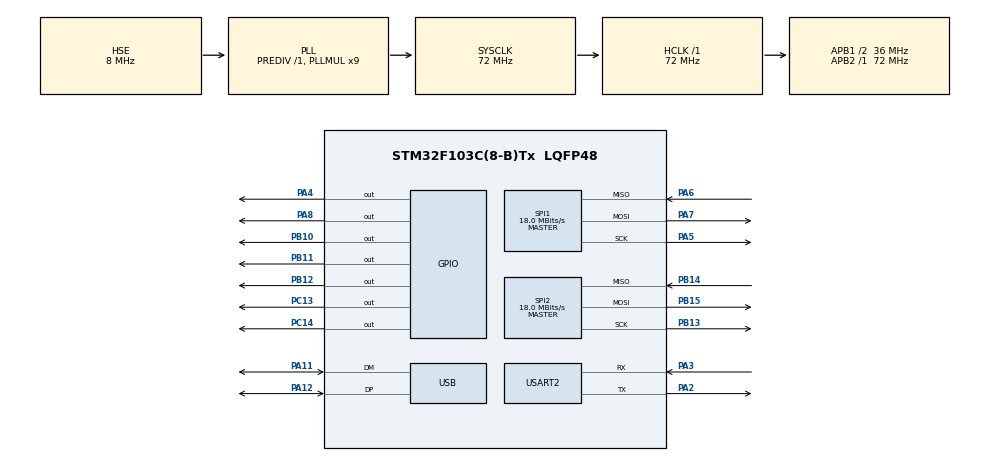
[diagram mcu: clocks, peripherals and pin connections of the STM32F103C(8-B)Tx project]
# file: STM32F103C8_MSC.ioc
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Dma.MEMTOMEM.0.Direction=DMA_MEMORY_TO_MEMORY
Dma.MEMTOMEM.0.Instance=DMA1_Channel1
Dma.MEMTOMEM.0.MemDataAlignment=DMA_MDATAALIGN_BYTE
Dma.MEMTOMEM.0.MemInc=DMA_MINC_ENABLE
Dma.MEMTOMEM.0.Mode=DMA_NORMAL
Dma.MEMTOMEM.0.PeriphDataAlignment=DMA_PDATAALIGN_BYTE
Dma.MEMTOMEM.0.PeriphInc=DMA_PINC_ENABLE
Dma.MEMTOMEM.0.Priority=DMA_PRIORITY_LOW
Dma.Request0=MEMTOMEM
Dma.Request1=SPI1_TX
Dma.Request2=SPI1_RX
Dma.Request3=USART2_RX
Dma.Request4=USART2_TX
Dma.SPI1_RX.2.Direction=DMA_PERIPH_TO_MEMORY
Dma.SPI1_RX.2.Instance=DMA1_Channel2
Dma.SPI1_RX.2.MemDataAlignment=DMA_MDATAALIGN_BYTE
Dma.SPI1_RX.2.MemInc=DMA_MINC_ENABLE
Dma.SPI1_RX.2.Mode=DMA_NORMAL
Dma.SPI1_RX.2.PeriphDataAlignment=DMA_PDATAALIGN_BYTE
Dma.SPI1_RX.2.PeriphInc=DMA_PINC_DISABLE
Dma.SPI1_RX.2.Priority=DMA_PRIORITY_LOW
Dma.SPI1_TX.1.Direction=DMA_MEMORY_TO_PERIPH
Dma.SPI1_TX.1.Instance=DMA1_Channel3
Dma.SPI1_TX.1.MemDataAlignment=DMA_MDATAALIGN_BYTE
Dma.SPI1_TX.1.MemInc=DMA_MINC_ENABLE
Dma.SPI1_TX.1.Mode=DMA_NORMAL
Dma.SPI1_TX.1.PeriphDataAlignment=DMA_PDATAALIGN_BYTE
Dma.SPI1_TX.1.PeriphInc=DMA_PINC_DISABLE
Dma.SPI1_TX.1.Priority=DMA_PRIORITY_LOW
Dma.USART2_RX.3.Direction=DMA_PERIPH_TO_MEMORY
Dma.USART2_RX.3.Instance=DMA1_Channel6
Dma.USART2_RX.3.MemDataAlignment=DMA_MDATAALIGN_BYTE
Dma.USART2_RX.3.MemInc=DMA_MINC_ENABLE
Dma.USART2_RX.3.Mode=DMA_NORMAL
Dma.USART2_RX.3.PeriphDataAlignment=DMA_PDATAALIGN_BYTE
Dma.USART2_RX.3.PeriphInc=DMA_PINC_DISABLE
Dma.USART2_RX.3.Priority=DMA_PRIORITY_LOW
Dma.USART2_TX.4.Direction=DMA_MEMORY_TO_PERIPH
Dma.USART2_TX.4.Instance=DMA1_Channel7
Dma.USART2_TX.4.MemDataAlignment=DMA_MDATAALIGN_BYTE
Dma.USART2_TX.4.MemInc=DMA_MINC_ENABLE
Dma.USART2_TX.4.Mode=DMA_NORMAL
Dma.USART2_TX.4.PeriphDataAlignment=DMA_PDATAALIGN_BYTE
Dma.USART2_TX.4.PeriphInc=DMA_PINC_DISABLE
Dma.USART2_TX.4.Priority=DMA_PRIORITY_LOW
FATFS._MAX_SS=4096
Mcu.Family=STM32F1
Mcu.Name=STM32F103C(8-B)Tx
Mcu.Package=LQFP48
NVIC.DMA1_Channel2_IRQn=true\:0\:0\:false\:false\:true\:false\:true
NVIC.DMA1_Channel3_IRQn=true\:0\:0\:false\:false\:true\:false\:true
NVIC.DMA1_Channel6_IRQn=true\:0\:0\:false\:false\:true\:false\:true
NVIC.DMA1_Channel7_IRQn=true\:0\:0\:false\:false\:true\:false\:true
NVIC.PriorityGroup=NVIC_PRIORITYGROUP_4
NVIC.USB_LP_CAN1_RX0_IRQn=true\:0\:0\:false\:false\:true\:false\:true
PA11.Mode=Device
PA11.Signal=USB_DM
PA12.Mode=Device
PA12.Signal=USB_DP
PA13.Mode=Serial_Wire
PA13.Signal=SYS_JTMS-SWDIO
PA14.Mode=Serial_Wire
PA14.Signal=SYS_JTCK-SWCLK
PA2.Mode=Asynchronous
PA2.Signal=USART2_TX
PA3.Mode=Asynchronous
PA3.Signal=USART2_RX
PA4.Signal=GPIO_Output
PA5.Mode=Full_Duplex_Master
PA5.Signal=SPI1_SCK
PA6.Mode=Full_Duplex_Master
PA6.Signal=SPI1_MISO
PA7.Mode=Full_Duplex_Master
PA7.Signal=SPI1_MOSI
PA8.Signal=GPIO_Output
PB10.Signal=GPIO_Output
PB11.Signal=GPIO_Output
PB12.Signal=GPIO_Output
PB13.Mode=Full_Duplex_Master
PB13.Signal=SPI2_SCK
PB14.Mode=Full_Duplex_Master
PB14.Signal=SPI2_MISO
PB15.Mode=Full_Duplex_Master
PB15.Signal=SPI2_MOSI
PC13-TAMPER-RTC.Signal=GPIO_Output
PC14-OSC32_IN.Signal=GPIO_Output
PD0-OSC_IN.Mode=HSE-External-Oscillator
PD0-OSC_IN.Signal=RCC_OSC_IN
PD1-OSC_OUT.Mode=HSE-External-Oscillator
PD1-OSC_OUT.Signal=RCC_OSC_OUT
ProjectManager.HeapSize=0x1000
ProjectManager.StackSize=0x2000
ProjectManager.TargetToolchain=MDK-ARM V5.27
RCC.AHBFreq_Value=72000000
RCC.APB1CLKDivider=RCC_HCLK_DIV2
RCC.APB1Freq_Value=36000000
RCC.APB1TimFreq_Value=72000000
RCC.APB2Freq_Value=72000000
RCC.APB2TimFreq_Value=72000000
RCC.HCLKFreq_Value=72000000
RCC.PLLMUL=RCC_PLL_MUL9
RCC.SYSCLKFreq_VALUE=72000000
RCC.SYSCLKSource=RCC_SYSCLKSOURCE_PLLCLK
RCC.USBFreq_Value=48000000
RCC.USBPrescaler=RCC_USBCLKSOURCE_PLL_DIV1_5
SPI1.BaudRatePrescaler=SPI_BAUDRATEPRESCALER_4
SPI1.CalculateBaudRate=18.0 MBits/s
SPI1.Direction=SPI_DIRECTION_2LINES
SPI1.Mode=SPI_MODE_MASTER
SPI1.VirtualType=VM_MASTER
SPI2.CalculateBaudRate=18.0 MBits/s
SPI2.Direction=SPI_DIRECTION_2LINES
SPI2.Mode=SPI_MODE_MASTER
SPI2.VirtualType=VM_MASTER
USART2.VirtualMode=VM_ASYNC
USB_DEVICE.CLASS_NAME_FS=MSC
USB_DEVICE.MSC_MEDIA_PACKET=4096
USB_DEVICE.USBD_DEBUG_LEVEL=0
USB_DEVICE.USBD_MAX_NUM_INTERFACES=3
USB_DEVICE.VID=0x0483
USB_DEVICE.VirtualMode=Msc
USB_DEVICE.VirtualModeFS=Msc_FS
VP_FATFS_VS_Generic.Mode=User_defined
VP_USB_DEVICE_VS_USB_DEVICE_MSC_FS.Mode=MSC_FS
board=custom

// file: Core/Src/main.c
/* USER CODE BEGIN Header */
/**
  ******************************************************************************
  * @file           : main.c
  * @brief          : Main program body
  ******************************************************************************
  * @attention
  *
  * <h2><center>&copy; Copyright (c) 2020 STMicroelectronics.
  * All rights reserved.</center></h2>
  *
  * This software component is licensed by ST under Ultimate Liberty license
  * SLA0044, the "License"; You may not use this file except in compliance with
  * the License. You may obtain a copy of the License at:
  *                             www.st.com/SLA0044
  *
  ******************************************************************************
  */
/* USER CODE END Header */

#include "main.h"
#include "dma.h"
#include "fatfs.h"
#include "spi.h"
#include "usart.h"
#include "usb_device.h"
#include "gpio.h"

/* USER CODE BEGIN Includes */
#include "usbd_custom_hid_if.h"
#include "usbd_cdc_if.h"

#include "DAP_config.h"
#include "hid_transfer.h"
#include "DAP.h"
#include "rl_usb.h"
#include "device.h"
#include "malloc.h"
/* USER CODE END Includes */

void SystemClock_Config(void);

int main(void)
{

  /* MCU Configuration--------------------------------------------------------*/

  /* Reset of all peripherals, Initializes the Flash interface and the Systick. */
  HAL_Init();

  /* USER CODE BEGIN Init */
char test[]="test\r\n";
  /* USER CODE END Init */

  /* Configure the system clock */
  SystemClock_Config();

  /* Initialize all configured peripherals */
  MX_GPIO_Init();
  MX_DMA_Init();
  MX_SPI1_Init();
  MX_USART2_UART_Init();
  MX_USB_DEVICE_Init();
  MX_SPI2_Init();
  MX_FATFS_Init();
  /* USER CODE BEGIN 2 */
//	while (!USBD_Configured(0U)){}         // Wait for USB Device to configure
	my_mem_init(SRAMIN);
  /* USER CODE END 2 */

  /* Infinite loop */
  while (1)
  {

    /* USER CODE BEGIN 3 */

//	CDC_Transmit_FS((uint8_t*)test,sizeof(test));
	HAL_Delay(10);
//	  hhid = (USBD_CUSTOM_HID_HandleTypeDef*) hUsbDeviceFS.pClassData;
//
//		usbd_hid_process();
		// USBD_CUSTOM_HID_SendReport(&hUsbDeviceFS,USB_Request[0],64);

	}
  /* USER CODE END 3 */
}

void SystemClock_Config(void)
{
  RCC_OscInitTypeDef RCC_OscInitStruct = {0};
  RCC_ClkInitTypeDef RCC_ClkInitStruct = {0};
  RCC_PeriphCLKInitTypeDef PeriphClkInit = {0};

  /** Initializes the CPU, AHB and APB busses clocks
  */
  RCC_OscInitStruct.OscillatorType = RCC_OSCILLATORTYPE_HSE;
  RCC_OscInitStruct.HSEState = RCC_HSE_ON;
  RCC_OscInitStruct.HSEPredivValue = RCC_HSE_PREDIV_DIV1;
  RCC_OscInitStruct.HSIState = RCC_HSI_ON;
  RCC_OscInitStruct.PLL.PLLState = RCC_PLL_ON;
  RCC_OscInitStruct.PLL.PLLSource = RCC_PLLSOURCE_HSE;
  RCC_OscInitStruct.PLL.PLLMUL = RCC_PLL_MUL9;
  if (HAL_RCC_OscConfig(&RCC_OscInitStruct) != HAL_OK)
  {
    Error_Handler();
  }
  /** Initializes the CPU, AHB and APB busses clocks
  */
  RCC_ClkInitStruct.ClockType = RCC_CLOCKTYPE_HCLK|RCC_CLOCKTYPE_SYSCLK
                              |RCC_CLOCKTYPE_PCLK1|RCC_CLOCKTYPE_PCLK2;
  RCC_ClkInitStruct.SYSCLKSource = RCC_SYSCLKSOURCE_PLLCLK;
  RCC_ClkInitStruct.AHBCLKDivider = RCC_SYSCLK_DIV1;
  RCC_ClkInitStruct.APB1CLKDivider = RCC_HCLK_DIV2;
  RCC_ClkInitStruct.APB2CLKDivider = RCC_HCLK_DIV1;

  if (HAL_RCC_ClockConfig(&RCC_ClkInitStruct, FLASH_LATENCY_2) != HAL_OK)
  {
    Error_Handler();
  }
  PeriphClkInit.PeriphClockSelection = RCC_PERIPHCLK_USB;
  PeriphClkInit.UsbClockSelection = RCC_USBCLKSOURCE_PLL_DIV1_5;
  if (HAL_RCCEx_PeriphCLKConfig(&PeriphClkInit) != HAL_OK)
  {
    Error_Handler();
  }
}

void Error_Handler(void)
{
}

/************************ (C) COPYRIGHT STMicroelectronics *****END OF FILE****/
